# APM32F41x register map
File version: 1.0
CPU: CM4 r1p0, little endian, no MPU, no FPU, 3 interrupt priority bits
Registers are 32-bit, read-write, reset 0x0 unless marked. A register's access mark holds for its fields unless they carry their own. Offsets are from the block's base; [hi:lo] are bit positions; lines under a group give offsets from that group; {n}, {i} and the like mark numbered series.

## SYSCFG — System configuration controller
Base 0x40013800
0x00 MMSEL — memory remap register
  [1:0] MMSEL — Memory Mapping Select
0x04 PMCFG — peripheral mode configuration register
  [23] ENETSEL — Ethernet PHY Interface Select
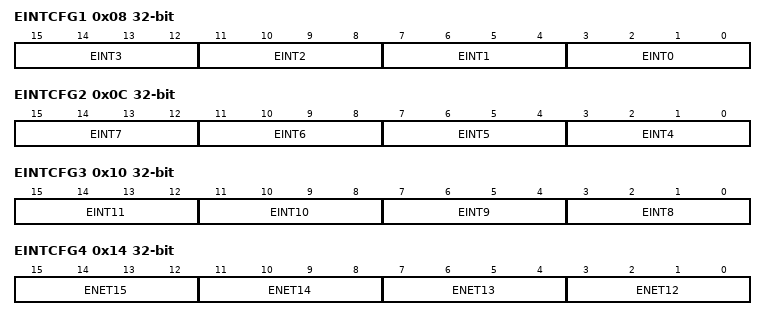
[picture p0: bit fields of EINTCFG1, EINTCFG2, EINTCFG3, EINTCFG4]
0x08 EINTCFG1 — external interrupt configuration register 1
  [4n+3:4n] EINT{n} (n=0..3) — EINTx Configure
0x0C EINTCFG2 — external interrupt configuration register 2
  [4n-13:4n-16] EINT{n} (n=4..7) — EINTx Configure
0x10 EINTCFG3 — external interrupt configuration register 3
  [4n-29:4n-32] EINT{n} (n=8..11) — EINTx Configure
0x14 EINTCFG4 — external interrupt configuration register 4
  [4n-45:4n-48] ENET{n} (n=12..15) — EINTx Configure
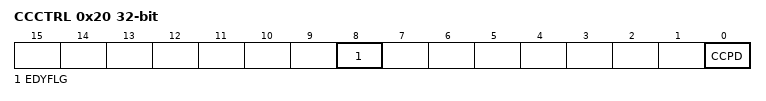
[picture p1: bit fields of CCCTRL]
0x20 CCCTRL access per field — Compensation cell control register
  [8] EDYFLG ro — Compensation Cell Ready Flag
  [0] CCPD rw — Compensation Cell Power-down

## ADC1 — Analog-to-digital converter
Base 0x40012000
Same registers: ADC2 0x40012100, ADC3 0x40012200
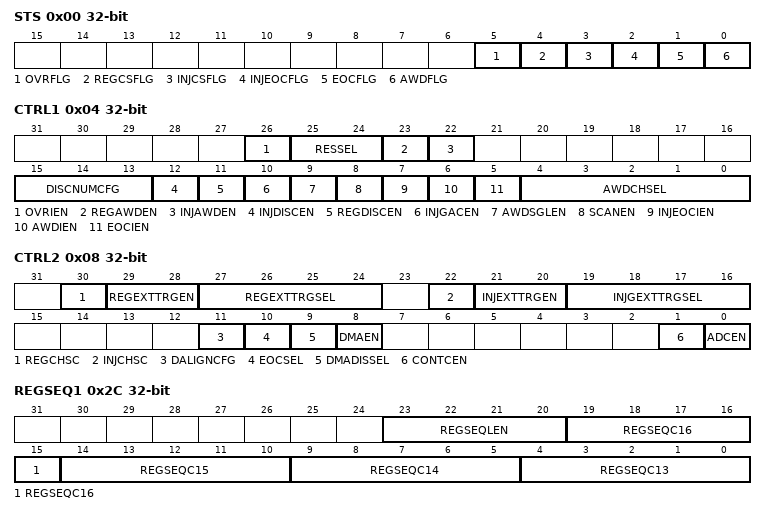
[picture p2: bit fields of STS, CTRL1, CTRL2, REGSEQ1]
0x00 STS — status register
  [5] OVRFLG — Overrun
  [4] REGCSFLG — Regular channel start flag
  [3] INJCSFLG — Injected channel start flag
  [2] INJEOCFLG — Injected channel end of conversion
  [1] EOCFLG — Regular channel end of conversion
  [0] AWDFLG — Analog watchdog flag
0x04 CTRL1 — control register 1
  [26] OVRIEN — Overrun interrupt enable
  [25:24] RESSEL — Resolution
  [23] REGAWDEN — Analog watchdog enable on regular channels
  [22] INJAWDEN — Analog watchdog enable on injected channels
  [15:13] DISCNUMCFG — Discontinuous mode channel count
  [12] INJDISCEN — Discontinuous mode on injected channels
  [11] REGDISCEN — Discontinuous mode on regular channels
  [10] INJGACEN — Automatic injected group conversion
  [9] AWDSGLEN — Enable the watchdog on a single channel in scan mode
  [8] SCANEN — Scan mode
  [7] INJEOCIEN — Interrupt enable for injected channels
  [6] AWDIEN — Analog watchdog interrupt enable
  [5] EOCIEN — Interrupt enable for EOC
  [4:0] AWDCHSEL — Analog watchdog channel select bits
0x08 CTRL2 — control register 2
  [30] REGCHSC — Start conversion of regular channels
  [29:28] REGEXTTRGEN — External trigger enable for regular channels
  [27:24] REGEXTTRGSEL — External event select for regular group
  [22] INJCHSC — Start conversion of injected channels
  [21:20] INJEXTTRGEN — External trigger enable for injected channels
  [19:16] INJGEXTTRGSEL — External event select for injected group
  [11] DALIGNCFG — Data alignment
  [10] EOCSEL — End of conversion selection
  [9] DMADISSEL — DMA disable selection (for single ADC mode)
  [8] DMAEN — Direct memory access mode (for single ADC mode)
  [1] CONTCEN — Continuous conversion
  [0] ADCEN — A/D Converter ON / OFF
0x0C SMPTIM1 — sample time register 1
  [31:0] SMPCYCCFG1 — Sample time bits
0x10 SMPTIM2 — sample time register 2
  [31:0] SMPCYCCFG2 — Sample time bits
{0x10+4i} INJDOF{i} (i=1..4) — injected channel data offset register {i}
  [11:0] INJDOF{i} — Data offset for injected channel {i}
0x24 AWDHT reset 0xFFF — watchdog higher threshold register
  [11:0] AWDHT — Analog watchdog higher threshold
0x28 AWDLT — watchdog lower threshold register
  [11:0] AWDLT — Analog watchdog lower threshold
0x2C REGSEQ1 — regular sequence register 1
  [23:20] REGSEQLEN — Regular channel sequence length
  [5n-61:5n-65] REGSEQC{n} (n=13..16) — {n}th conversion in regular sequence
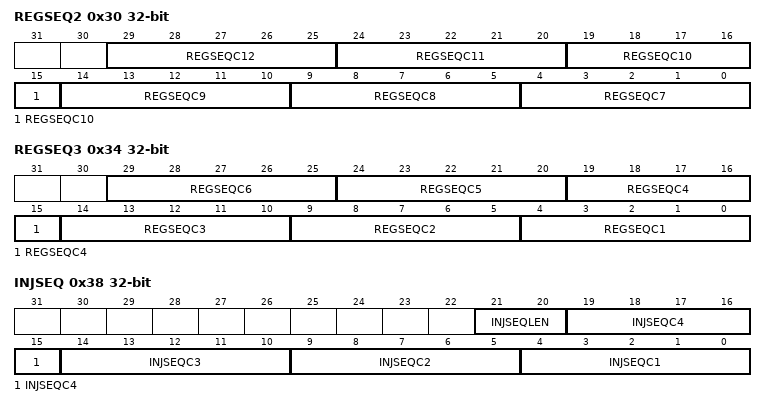
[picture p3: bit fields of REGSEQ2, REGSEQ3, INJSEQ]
0x30 REGSEQ2 — regular sequence register 2
  [5n-31:5n-35] REGSEQC{n} (n=7..12) — {n}th conversion in regular sequence
0x34 REGSEQ3 — regular sequence register 3
  [29:25] REGSEQC6 — 6th conversion in regular sequence
  [24:20] REGSEQC5 — 5th conversion in regular sequence
  [19:15] REGSEQC4 — 4th conversion in regular sequence
  [14:10] REGSEQC3 — 3rd conversion in regular sequence
  [9:5] REGSEQC2 — 2nd conversion in regular sequence
  [4:0] REGSEQC1 — 1st conversion in regular sequence
0x38 INJSEQ — injected sequence register
  [21:20] INJSEQLEN — Injected sequence length
  [19:15] INJSEQC4 — 4th conversion in injected sequence
  [14:10] INJSEQC3 — 3rd conversion in injected sequence
  [9:5] INJSEQC2 — 2nd conversion in injected sequence
  [4:0] INJSEQC1 — 1st conversion in injected sequence
{0x38+4i} INJDATA{i} ro (i=1..4) — injected data register x
  [15:0] INJDATA — Injected data
0x4C REGDATA ro — regular data register
  [15:0] REGDATA — Regular data
